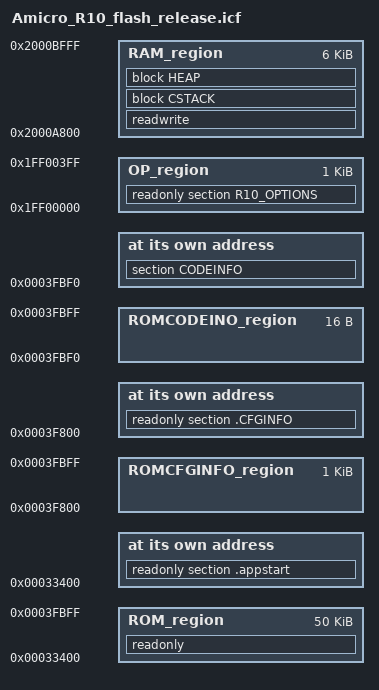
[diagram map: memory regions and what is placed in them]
/*###ICF### Section handled by ICF editor, don't touch! ****/
/*-Memory Regions-*/
define symbol __ICFEDIT_region_ROM_start__ = 0x00033400;
define symbol __ICFEDIT_region_ROM_end__   = 0x0003FBFF;

define symbol __ICFEDIT_region_RAM_start__ = 0x2000a800;
define symbol __ICFEDIT_region_RAM_end__   = 0x2000BFFF;

define symbol __ICFEDIT_region_ROMCFGINFOSTART_start__ = 0x0003F800;
define symbol __ICFEDIT_region_ROMCFGINFOSTART_end__   = 0x0003FBFF;

define symbol __ICFEDIT_region_ROMCODEINFOSTART_start__ = 0x0003FBF0;
define symbol __ICFEDIT_region_ROMCODEINFOSTART_end__   = 0x0003FBFF;
/**** End of ICF editor section. ###ICF###*/
define symbol __ICFEDIT_size_cstack__ = 0x0;
define symbol __ICFEDIT_size_heap__   = 0x0;

define block CSTACK    with alignment = 8, size = __ICFEDIT_size_cstack__   { };
define block HEAP      with alignment = 8, size = __ICFEDIT_size_heap__     { };

define memory mem with size = 4G;
define region ROM_region   = mem:[from __ICFEDIT_region_ROM_start__   to __ICFEDIT_region_ROM_end__];
define region RAM_region   = mem:[from __ICFEDIT_region_RAM_start__   to __ICFEDIT_region_RAM_end__];
define region ROMCODEINO_region   = mem:[from __ICFEDIT_region_ROMCODEINFOSTART_start__   to __ICFEDIT_region_ROMCODEINFOSTART_end__];
define region ROMCFGINFO_region   = mem:[from __ICFEDIT_region_ROMCFGINFOSTART_start__   to __ICFEDIT_region_ROMCFGINFOSTART_end__];


initialize by copy { readwrite };
do not initialize  { section .noinit };

place at address mem:__ICFEDIT_region_ROMCODEINFOSTART_start__{section CODEINFO};
place at address mem:__ICFEDIT_region_ROMCFGINFOSTART_start__ {readonly section .CFGINFO};
place at address mem: __ICFEDIT_region_ROM_start__ { readonly section .appstart };
place in ROM_region   { readonly };
place in RAM_region   { readwrite,block CSTACK , block HEAP};

define symbol op_rom_start       = 0x1FF00000;
define symbol op_rom_end         = 0x1FF003FF;
define region OP_region    = mem:[from op_rom_start to op_rom_end];
place in OP_region    { readonly section R10_OPTIONS };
